# STM32F103_MINI register map
Registers are access not given, reset 0x0 unless marked. A register's access mark holds for its fields unless they carry their own. Offsets are from the block's base; lines under a group give offsets from that group; [hi:lo] are bit positions; {n}, {i} and the like mark numbered series; 'fields as' and 'values as' point back to an identical list; <NAME> marks a mode.

## Memory map
0x40010800 GPIOA size 0x400
0x40010C00 GPIOB size 0x400
0x40013800 USART1 size 0x400
0x40021000 RCC size 0x400

## Interrupts
37 USART1

## RCC
Base 0x40021000
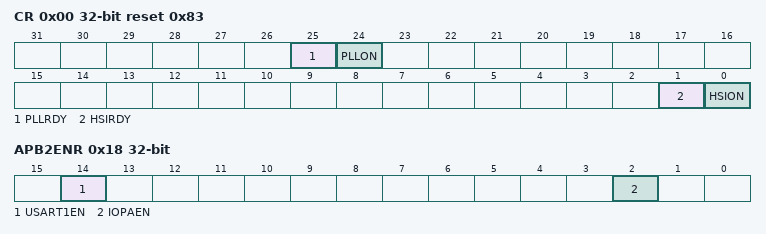
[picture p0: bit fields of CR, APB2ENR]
0x00 CR reset 0x83
  [25] PLLRDY, [24] PLLON, [1] HSIRDY, [0] HSION
0x18 APB2ENR
  [14] USART1EN, [2] IOPAEN

## GPIOA
Base 0x40010800
Same registers: GPIOB 0x40010C00
0x00 CRL reset 0x44444444
0x08 IDR
0x0C ODR
0x10 BSRR

## USART1
Base 0x40013800
0x00 SR reset 0xC0
0x04 DR
